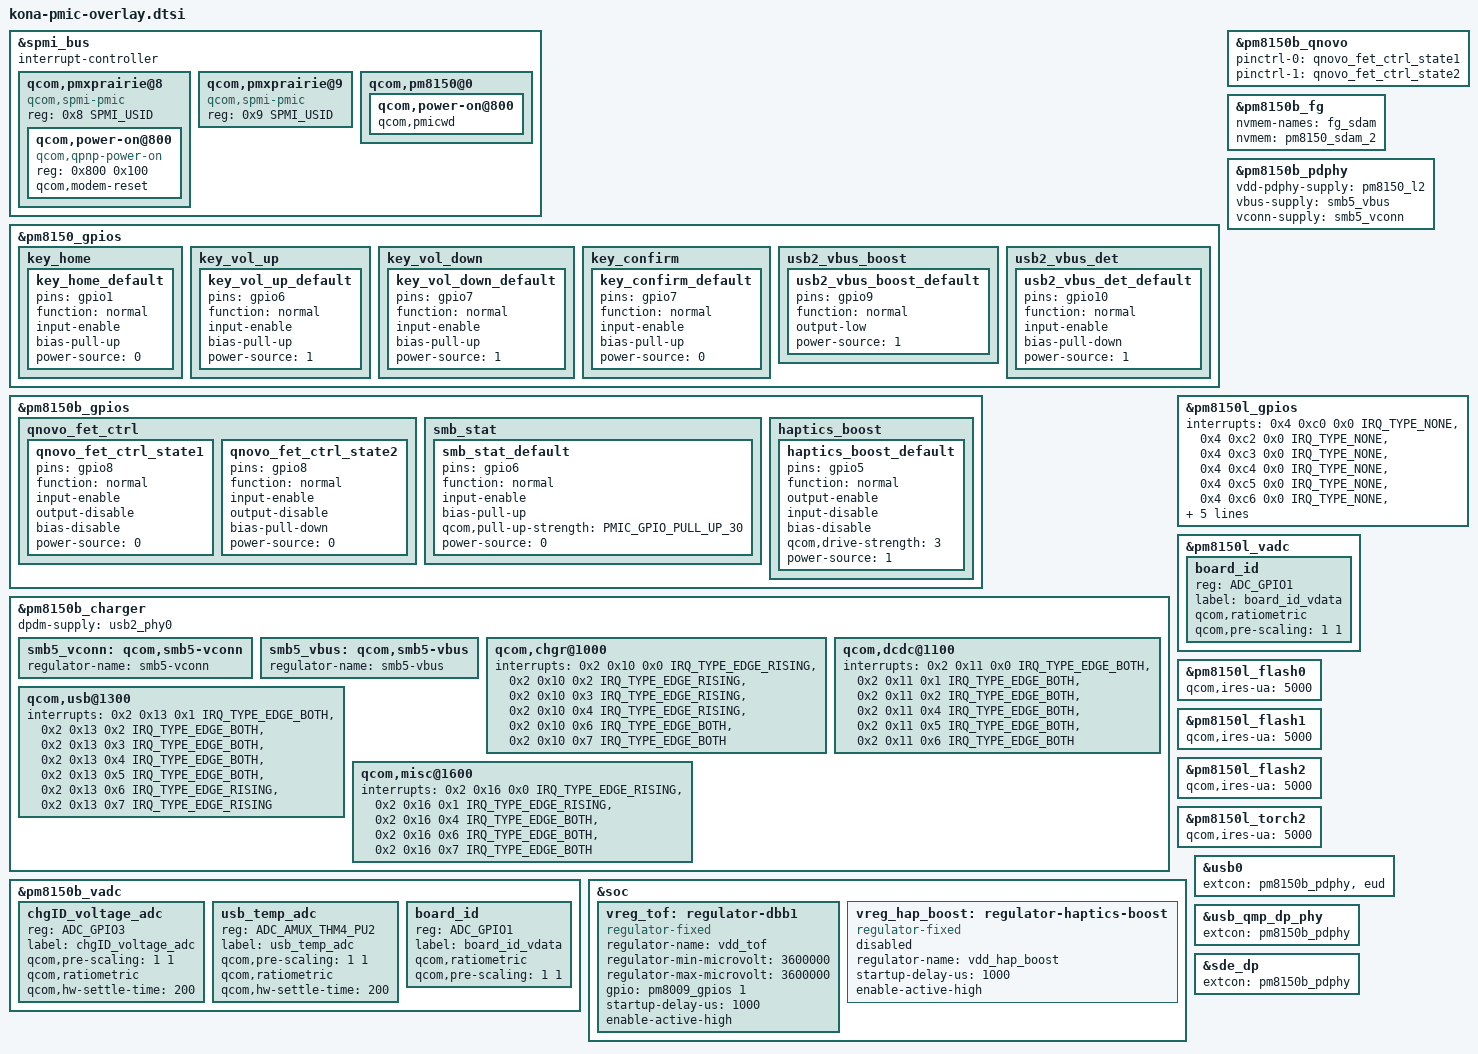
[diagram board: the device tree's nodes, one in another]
#include <dt-bindings/gpio/gpio.h>
#include <dt-bindings/pinctrl/qcom,pmic-gpio.h>

#include "../../qcom/pm8150.dtsi"
#include "../../qcom/pm8150b.dtsi"
#include "../../qcom/pm8150l.dtsi"
#include "../../qcom/pm8009.dtsi"

&spmi_bus {
	#address-cells = <2>;
	#size-cells = <0>;
	interrupt-controller;
	#interrupt-cells = <4>;

	qcom,pmxprairie@8 {
		compatible = "qcom,spmi-pmic";
		reg = <0x8 SPMI_USID>;
		#address-cells = <2>;
		#size-cells = <0>;

		qcom,power-on@800 {
			compatible = "qcom,qpnp-power-on";
			reg = <0x800 0x100>;
			qcom,modem-reset;
		};
	};

	qcom,pmxprairie@9 {
		compatible ="qcom,spmi-pmic";
		reg = <0x9 SPMI_USID>;
		#address-cells = <2>;
		#size-cells = <0>;
	};

	//#ifdef OPLUS_FEATURE_QCOM_PMICWD
	qcom,pm8150@0 {
		qcom,power-on@800 {
			qcom,pmicwd;
		};
	};
	//#endif /* OPLUS_FEATURE_QCOM_PMICWD */
};

&pm8150_gpios {
	key_home {
		key_home_default: key_home_default {
			pins = "gpio1";
			function = "normal";
			input-enable;
			bias-pull-up;
			power-source = <0>;
		};
	};

	key_vol_up {
		key_vol_up_default: key_vol_up_default {
			pins = "gpio6";
			function = "normal";
			input-enable;
			bias-pull-up;
			power-source = <1>;
		};
	};
	//#ifdef OPLUS_FEATURE_TP_BASIC
	key_vol_down {
		key_vol_down_default: key_vol_down_default {
			pins = "gpio7";
			function = "normal";
			input-enable;
			bias-pull-up;
			power-source = <1>;
		};
	};
	//#endif

	key_confirm {
		key_confirm_default: key_confirm_default {
			pins = "gpio7";
			function = "normal";
			input-enable;
			bias-pull-up;
			power-source = <0>;
		};
	};

	usb2_vbus_boost {
		usb2_vbus_boost_default: usb2_vbus_boost_default {
			pins = "gpio9";
			function = "normal";
			output-low;
			power-source = <1>;	/* 1.8V input supply */
		};
	};

	usb2_vbus_det {
		usb2_vbus_det_default: usb2_vbus_det_default {
			pins = "gpio10";
			function = "normal";
			input-enable;
			bias-pull-down;
			power-source = <1>;	/* 1.8V input supply */
		};
	};
};

&pm8150b_gpios {
	qnovo_fet_ctrl {
		qnovo_fet_ctrl_state1: qnovo_fet_ctrl_state1 {
			pins = "gpio8";
			function = "normal";
			input-enable;
			output-disable;
			bias-disable;
			power-source = <0>;
		};

		qnovo_fet_ctrl_state2: qnovo_fet_ctrl_state2 {
			pins = "gpio8";
			function = "normal";
			input-enable;
			output-disable;
			bias-pull-down;
			power-source = <0>;
		};
	};

	smb_stat {
		smb_stat_default: smb_stat_default {
			  pins = "gpio6";
			  function = "normal";
			  input-enable;
			  bias-pull-up;
			  qcom,pull-up-strength = <PMIC_GPIO_PULL_UP_30>;
			  power-source = <0>;
		  };
	};
};

&pm8150b_qnovo {
	pinctrl-names = "q_state1", "q_state2";
	pinctrl-0 = <&qnovo_fet_ctrl_state1>;
	pinctrl-1 = <&qnovo_fet_ctrl_state2>;
};

&pm8150b_fg {
	nvmem-names = "fg_sdam";
	nvmem = <&pm8150_sdam_2>;
};

&pm8150b_charger {
	dpdm-supply = <&usb2_phy0>;
	smb5_vconn: qcom,smb5-vconn {
		regulator-name = "smb5-vconn";
	};

	smb5_vbus: qcom,smb5-vbus {
		regulator-name = "smb5-vbus";
	};

	qcom,chgr@1000 {
		interrupts = <0x2 0x10 0x0 IRQ_TYPE_EDGE_RISING>,
					<0x2 0x10 0x2 IRQ_TYPE_EDGE_RISING>,
					<0x2 0x10 0x3 IRQ_TYPE_EDGE_RISING>,
					<0x2 0x10 0x4 IRQ_TYPE_EDGE_RISING>,
					<0x2 0x10 0x6 IRQ_TYPE_EDGE_BOTH>,
					<0x2 0x10 0x7 IRQ_TYPE_EDGE_BOTH>;
		interrupt-names = "chgr-error",
						"step-chg-state-change",
						"step-chg-soc-update-fail",
						"step-chg-soc-update-req",
						"vph-alarm",
						"vph-drop-prechg";
	};

	qcom,dcdc@1100 {
		interrupts = <0x2 0x11 0x0 IRQ_TYPE_EDGE_BOTH>,
					<0x2 0x11 0x1 IRQ_TYPE_EDGE_BOTH>,
					<0x2 0x11 0x2 IRQ_TYPE_EDGE_BOTH>,
					<0x2 0x11 0x4 IRQ_TYPE_EDGE_BOTH>,
					<0x2 0x11 0x5 IRQ_TYPE_EDGE_BOTH>,
					<0x2 0x11 0x6 IRQ_TYPE_EDGE_BOTH>;

		interrupt-names = "otg-fail",
						"otg-oc-disable-sw",
						"otg-oc-hiccup",
						"high-duty-cycle",
						"input-current-limiting",
						"concurrent-mode-disable";
	};

	qcom,usb@1300 {
		interrupts = <0x2 0x13 0x1 IRQ_TYPE_EDGE_BOTH>,
					<0x2 0x13 0x2 IRQ_TYPE_EDGE_BOTH>,
					<0x2 0x13 0x3 IRQ_TYPE_EDGE_BOTH>,
					<0x2 0x13 0x4 IRQ_TYPE_EDGE_BOTH>,
					<0x2 0x13 0x5 IRQ_TYPE_EDGE_BOTH>,
					<0x2 0x13 0x6 IRQ_TYPE_EDGE_RISING>,
					<0x2 0x13 0x7 IRQ_TYPE_EDGE_RISING>;
		interrupt-names = "usbin-vashdn",
						"usbin-uv",
						"usbin-ov",
						"usbin-plugin",
						"usbin-revi-change",
						"usbin-src-change",
						"usbin-icl-change";
	};

	qcom,misc@1600 {
		interrupts = <0x2 0x16 0x0 IRQ_TYPE_EDGE_RISING>,
					<0x2 0x16 0x1 IRQ_TYPE_EDGE_RISING>,
					<0x2 0x16 0x4 IRQ_TYPE_EDGE_BOTH>,
					<0x2 0x16 0x6 IRQ_TYPE_EDGE_BOTH>,
					<0x2 0x16 0x7 IRQ_TYPE_EDGE_BOTH>;
		interrupt-names = "wdog-snarl",
						"wdog-bark",
						"smb-en",
						"temp-change",
						"temp-change-smb";
	};
};

&pm8150b_pdphy {
	vdd-pdphy-supply = <&pm8150_l2>;
	vbus-supply = <&smb5_vbus>;
	vconn-supply = <&smb5_vconn>;
};

&pm8150b_gpios {
	haptics_boost {
		haptics_boost_default: haptics_boost_default {
			pins = "gpio5";
			function = "normal";
			output-enable;
			input-disable;
			bias-disable;
			qcom,drive-strength = <3>; /* high */
			power-source = <1>; /* 1.8 V */
		};
	};
};

&pm8150b_vadc {
	chgID_voltage_adc {
		reg = <ADC_GPIO3>;
		label = "chgID_voltage_adc";
		qcom,pre-scaling = <1 1>;
		qcom,ratiometric;
		qcom,hw-settle-time = <200>;
	};

	usb_temp_adc {
		reg = <ADC_AMUX_THM4_PU2>;
		label = "usb_temp_adc";
		qcom,pre-scaling = <1 1>;
		qcom,ratiometric;
		qcom,hw-settle-time = <200>;
	};

	board_id {
		reg = <ADC_GPIO1>;
		label = "board_id_vdata";
		qcom,ratiometric;
		qcom,pre-scaling = <1 1>;
	};
};

&pm8150l_gpios {
	interrupts = <0x4 0xc0 0x0 IRQ_TYPE_NONE>,
			<0x4 0xc2 0x0 IRQ_TYPE_NONE>,
			<0x4 0xc3 0x0 IRQ_TYPE_NONE>,
			<0x4 0xc4 0x0 IRQ_TYPE_NONE>,
			<0x4 0xc5 0x0 IRQ_TYPE_NONE>,
			<0x4 0xc6 0x0 IRQ_TYPE_NONE>,
			<0x4 0xc7 0x0 IRQ_TYPE_NONE>,
			<0x4 0xc8 0x0 IRQ_TYPE_NONE>,
			<0x4 0xc9 0x0 IRQ_TYPE_NONE>,
			<0x4 0xca 0x0 IRQ_TYPE_NONE>;
	interrupt-names = "pm8150l_gpio1", "pm8150l_gpio3",
			"pm8150l_gpio4", "pm8150l_gpio5",
			"pm8150l_gpio6", "pm8150l_gpio7",
			"pm8150l_gpio8", "pm8150l_gpio9",
			"pm8150l_gpio10", "pm8150l_gpio11";
	qcom,gpios-disallowed = <2 12>;
};

&pm8150l_vadc {
	board_id {
		reg = <ADC_GPIO1>;
		label = "board_id_vdata";
		qcom,ratiometric;
		qcom,pre-scaling = <1 1>;
	};
};

&pm8150l_flash0 {
	qcom,ires-ua = <5000>;
};

&pm8150l_flash1 {
	qcom,ires-ua = <5000>;
};

&pm8150l_flash2 {
	qcom,ires-ua = <5000>;
};

&pm8150l_torch2 {
	qcom,ires-ua = <5000>;
};

&soc {
	vreg_tof: regulator-dbb1 {
		compatible = "regulator-fixed";
		regulator-name = "vdd_tof";
		regulator-min-microvolt = <3600000>;
		regulator-max-microvolt = <3600000>;
		gpio = <&pm8009_gpios 1 GPIO_ACTIVE_HIGH>;
		startup-delay-us = <1000>;
		enable-active-high;
	};

	vreg_hap_boost: regulator-haptics-boost {
		compatible = "regulator-fixed";
		regulator-name = "vdd_hap_boost";
		//gpio = <&pm8150b_gpios 5 GPIO_ACTIVE_HIGH>;
		//pinctrl-names = "default";
		//pinctrl-0 = <&haptics_boost_default>;
		startup-delay-us = <1000>;
		enable-active-high;
		status = "disabled";
	};
};

&usb0 {
	extcon = <&pm8150b_pdphy>, <&eud>;
};

&usb_qmp_dp_phy {
	 extcon = <&pm8150b_pdphy>;
};

&sde_dp {
	extcon = <&pm8150b_pdphy>;
};
